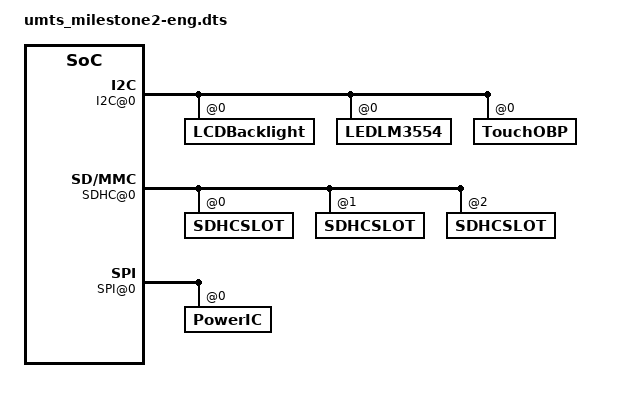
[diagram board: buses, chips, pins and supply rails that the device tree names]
/* Motorola Milestone 2 - engineering version */

/dts-v1/;

/ {

	Aliases@0 {
	};

	Chosen@0 {
		bp_model = "UMTS";
		formfactor = <0x3>;
		last_compat_version = <0x132b7fc>;
		product = <0x1220>;
		usb_id_prod_name = "NS A953";
		version = <0x132b7fc>;
	};

	Machine@0 {
	};

	System@0 {

		Display@0 {
			byte_pp = [03];
			class = "Display";
			disp_hw_type = [04];
			disp_intf = [04];
			dispc_timing_hbp = [02 00];
			dispc_timing_hfp = [00 00];
			dispc_timing_hsw = [02 00];
			dispc_timing_vbp = [01 00];
			dispc_timing_vfp = [00 00];
			dispc_timing_vsw = [01 00];
			dsi_clk_lane = [01];
			dsi_clk_pol = [00];
			dsi_data1_lane = [02];
			dsi_data1_pol = [00];
			dsi_data2_lane = [03];
			dsi_data2_pol = [00];
			gpio_reset = <0x88>;
			height = [56 03];
			lck_div = [01 00];
			lp_clk_div = [07 00];
			pck_div = [04 00];
			phy_height_mm = [52 00];
			phy_width_mm = [2e 00];
			pixel_fmt = <0x5>;
			regm = [aa 00];
			regm3 = [05 00];
			regm4 = [05 00];
			regn = [0d 00];
			te_scan_line = <0x200>;
			type = <0x1a0001>;
			width = [e0 01];
		};

		DisplayBacklight@0 {
			class = "DisplayBacklight";
			ruth_lcd = [00];
			tablet_lcd = [01];
			type = <0xd>;
		};

		Feature@0 {
			class = "Feature";
			feature_cam_regulators = "vcam";
			feature_hdmi = [00];
			feature_headset_uart_en = [00];
			feature_mipi_cam = [00];
			feature_no_nand = [01];
			type = <0xf>;
		};

		GPIO@0 {
			class = "GPIO";
			signalmap = <0x1c 0x386d6b61 0x5f333739 0x65736572 0x20202074 0x202020 0x5c 0x5f736c61 0x20746e69 0x20202020 0x20202020 0x202020 0xaf 0x386d6b61 0x5f333739 0x20746e69 0x20202020 0x202020 0x15 0x725f7462 0x74657365 0x2020625f 0x20202020 0x202020 0x8 0x775f7462 0x5f656b61 0x20202062 0x20202020 0x202020 0xf 0x685f7462 0x5f74736f 0x656b6177 0x2020625f 0x202020 0xba 0x6e616c77 0x7365725f 0x20207465 0x20202020 0x202020 0x64 0x656c6973 0x5f65636e 0x61746164 0x20202020 0x202020 0xb6 0x5f626976 0x746e6f63 0x5f6c6f72 0x20206e65 0x202020 0xb0 0x65776f70 0x666f5f72 0x20202066 0x20202020 0x202020 0x63 0x63756f74 0x61705f68 0x5f6c656e 0x20746e69 0x202020 0x2a 0x655f6d66 0x6c62616e 0x20202065 0x20202020 0x202020 0x10 0x786f7270 0x74696d69 0x6e695f79 0x20202074 0x202020 0x7e 0x64616568 0x5f746573 0x74726175 0x6977735f 0x686374 0xa4 0x63756f74 0x61705f68 0x5f6c656e 0x20747372 0x202020 0x5c 0x35336d6c 0x695f3033 0x2020746e 0x20202020 0x202020 0x5d 0x35336d6c 0x725f3033 0x74657365 0x20202020 0x202020 0x62 0x6f697067 0x6d61635f 0x7365725f 0x20207465 0x202020>;
			type = <0x30003>;

			HallEffect@0 {
				class = "HallEffect";
				device_available = [01];
				type = <0x170000>;
			};
		};

		GPIODev@0 {
			class = "GPIODev";
			init = <0x3b 0x5f737067 0x65736572 0x20202074 0x20202020 0x202020 0x8 0x17 0x5f737067 0x6e617473 0x20796264 0x20202020 0x202020 0x8 0x8 0x775f7462 0x20656b61 0x20202020 0x20202020 0x202020 0x8 0xf 0x685f7462 0x7774736f 0x20656b61 0x20202020 0x202020 0x2>;
			type = <0x3000a>;
		};

		I2C@0 {
			bus1devices = "qtouch-obp-ts,lm3530_led,airc";
			bus2devices = "akm8973,lis331dlh";
			bus3devices = "HP_GEN_LENS,mt9p012,lm3554_led";
			class = "I2C";
			type = <0x10003>;

			LCDBacklight@0 {
				als_config = [2d];
				als_resistor_sel = [83];
				als_zone_info = [00];
				brightness_control = [00];
				brightness_ramp = [00];
				class = "LCDBacklight";
				gen_config = [3f];
				lens_loss_coeff = [04];
				lower_curr_sel = [03];
				manual_als_config = [64];
				manual_current = [37];
				power_up_gen_config = [27];
				type = <0xb0002>;
				upper_curr_sel = [06];
				zone_boundary_0 = [04];
				zone_boundary_1 = [59];
				zone_boundary_2 = [fa];
				zone_boundary_3 = [fa];
				zone_target_0 = [18];
				zone_target_1 = [36];
				zone_target_2 = [67];
				zone_target_3 = [7b];
				zone_target_4 = [7b];
			};

			LEDLM3554@0 {
				class = "LEDLM3554";
				device_available = <0x1>;
				type = <0xb0001>;
			};

			TouchOBP@0 {
				abs_max_w = <0x23>;
				class = "TouchOBP";
				nv_checksum = <0xf8f1>;
				obj_t9 = [0b 00 00 0c 07 00 40 12 02 00 19 05 05 00 05 00 03 00 00 00 00 00 00 00 00 00 00 00 00 00];
				touch_key_map = <0x8b 0x20 0x38a 0x3f 0x39 0x66 0xa2 0x38a 0x59 0x39 0x9e 0x124 0x38a 0x59 0x39 0xd9 0x1b7 0x38a 0x3f 0x39>;
				type = <0x70006>;
			};
		};

		IOMUX@0 {
			class = "IOMUX";
			offmodeinit = <0x100007a 0x7c0100 0x1000100 0x100007e 0x800100 0x1000100 0x1000082 0x840100 0x1000100 0x1000086 0x880100 0x1000100 0x10000be 0xd20101 0x1000100 0x1000116 0x1180100 0x1000100 0x100012e 0x1080100 0x1000100 0x1000194 0x1d60100 0x1000100 0x10001da 0x1d00100 0x1000100 0x10005ec 0x5f00100 0x1000100 0x10001d4 0x1d20100 0x100>;
			offmodewkupsinit = [1a 0a 01 01 00 00];
			padinit = [be 00 04 01 01 d2 00 04 01 00 64 02 00 00 00 48 01 00 01 03 4a 01 00 01 03 4c 01 00 01 03 4e 01 00 01 03 50 01 07 00 00 52 01 07 00 00 54 01 07 00 00 56 01 07 00 00 58 01 00 01 00 5a 01 00 01 03 5c 01 00 01 03 5e 01 00 01 03 60 01 00 01 03 62 01 00 01 03 c8 01 01 01 03 ca 01 01 01 03 cc 01 01 01 03 ce 01 01 01 03 72 01 05 01 01 80 01 05 01 01 88 01 05 01 01 86 01 05 01 01 8a 01 05 01 01 84 01 05 01 01 8e 01 01 01 00 8c 01 02 01 01 94 01 04 01 01 d8 05 02 01 00 da 05 02 01 03 de 05 04 01 01 e2 05 02 01 03 e4 05 02 01 03 e6 05 02 01 03 e8 05 02 01 03 da 01 00 01 01 9a 01 04 01 00 9c 01 04 00 03 ec 05 04 01 01 f0 05 04 01 00 f8 05 04 00 00 e2 01 04 00 00 d6 01 00 01 03 d8 01 00 00 00 dc 01 00 00 00 de 01 04 01 03 be 01 00 01 03 c0 01 00 01 03 2e 01 04 01 00 2c 01 00 01 00 2a 01 00 01 00 16 01 04 01 00 18 01 04 01 00 d2 01 04 00 00 d4 00 07 00 00 d6 00 07 00 00 d8 00 07 00 00 da 00 07 00 00 dc 00 01 00 00 de 00 01 00 00 e0 00 01 00 00 e2 00 01 00 00 e4 00 01 00 00 e6 00 01 00 00 e8 00 07 00 00 ea 00 07 00 00 ec 00 07 00 00 ee 00 07 00 00 f0 00 07 00 00 f2 00 07 00 00 f4 00 07 00 00 f6 00 07 00 00 f8 00 07 00 00 fa 00 07 00 00 fc 00 07 00 00 fe 00 07 00 00 00 01 07 00 00 02 01 07 00 00 04 01 07 00 00 06 01 07 00 00 08 01 04 01 00 30 01 07 00 00 32 01 04 00 01 34 01 07 00 00 36 01 07 00 00 38 01 07 00 00 3a 01 07 00 00 f4 05 03 01 01 f6 05 00 01 01];
			padwkupsinit = [16 0a 04 00 00 1a 0a 04 01 00 18 0a 07 00 00];
			type = <0x30004>;
		};

		Keypad@0 {
			class = "Keypad";
			closed_maps = <0x0 0x720000 0x730000 0x0 0x0 0x0 0x0 0x0 0x0 0x0 0x0 0x0 0x0 0x0 0x0 0x0 0x0 0xd30000 0xd40000 0x0 0x0 0x0 0x0 0x0 0x0 0x0 0x0 0x0 0x0 0x0 0x0 0x0>;
			keycodes-bugtogo = <0x2a 0xe>;
			maps = <0x13000a 0x7200e7 0x73003e 0x2000d9 0x320008 0x250026 0x2e0031 0x2a002c 0x150002 0x330017 0x340038 0x120022 0x70000 0x6c0004 0x690067 0xe8006a 0x240006 0xd30030 0xd40014 0x2d0000 0x390009 0x9e000f 0xa70035 0x1e000e 0xb0003 0x21 0x18001c 0x100023 0x2f0005 0x19001f 0xd7007d 0x110016>;
			name = "umts_milestone2-keypad";
			type = <0x1>;
		};

		LEDController@0 {
			class = "LEDController";
			dev_name = "button-backlight";
			type = <0x210003>;
		};

		LEDController@1 {
			class = "LEDController";
			dev_name = "keyboard-backlight";
			type = <0x210002>;
		};

		LEDController@2 {
			class = "LEDController";
			dev_name_blue = "blue";
			dev_name_green = "green";
			dev_name_red = "red";
			type = <0x210005>;
		};

		SDHC@0 {
			class = "SDHC";
			type = <0x30008>;

			SDHCSLOT@0 {
				card_connect = <0x1>;
				card_detection = <0x1>;
				host_capability = <0x11>;
				pwr_supply = <0x1>;
			};

			SDHCSLOT@1 {
				card_connect = <0x2>;
				card_detection = <0x0>;
				host_capability = <0x111>;
			};

			SDHCSLOT@2 {
				card_connect = <0x3>;
				card_detection = <0x1>;
				host_capability = <0x11>;
				sdcnum = [03];
			};
		};

		SPI@0 {
			class = "SPI";
			type = <0x30007>;

			PowerIC@0 {
				bus_num = [02 00];
				class = "PowerIC";
				regulator_init = [06 00 00 00 40 77 1b 00 40 77 1b 00 08 00 00 00 00 01 01 08 00 00 00 38 9c 1c 00 38 9c 1c 00 01 00 00 00 01 00 01 0d 00 00 00 d8 57 2a 00 d8 57 2a 00 09 00 00 00 01 00 01 0e 00 00 00 d8 57 2a 00 d8 57 2a 00 09 00 00 00 01 00 01 0f 00 00 00 d8 57 2a 00 d8 57 2a 00 09 00 00 00 01 00 01 12 00 00 00 40 77 1b 00 20 40 2c 00 09 00 00 00 00 00 00 13 00 00 00 40 77 1b 00 20 40 2c 00 09 00 00 00 00 00 00];
				regulator_mode = <0x6 0x80043 0x820000 0xd 0xe0024 0x10000 0xf 0x160023 0x140000>;
				regulator_off_mode = [06 00 00 00 41 00];
				spiinit = <0x2e 0xdb04 0x36 0x4034 0x37 0x3434 0x9c 0x0>;
				type = <0x30006>;
			};
		};

		UART@0 {
			class = "UART";
			gps_port = <0x1>;
			hw_flow_control = [40 c0 40];
			type = <0x3000b>;
		};

		VideoOut@0 {
			class = "VideoOut";
			max_buffer_size = <0x1c3000>;
			max_height = [d0 02];
			max_width = [00 05];
			type = <0xe>;
		};
	};
};
